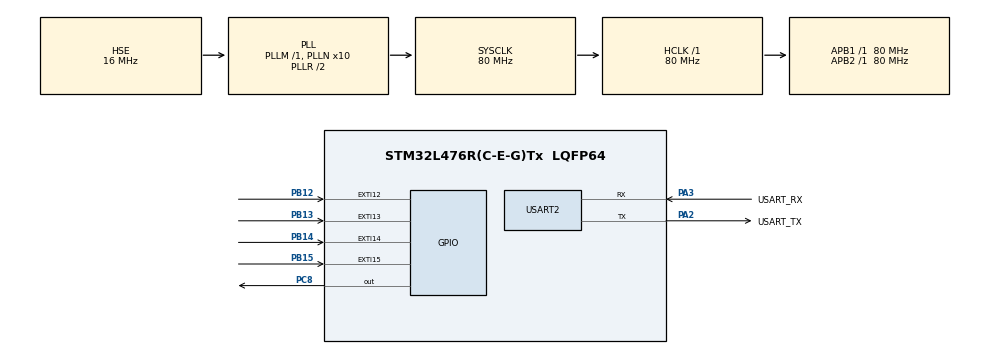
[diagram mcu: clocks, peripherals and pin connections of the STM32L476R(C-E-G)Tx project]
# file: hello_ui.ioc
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Mcu.Family=STM32L4
PA2.GPIO_PuPd=GPIO_NOPULL
VP_SYS_VS_tim6.Mode=TIM6
RCC.CortexFreq_Value=80000000
NVIC.TIM6_DAC_IRQn=true\:0\:0\:false\:false\:true\:false\:false\:true
PH0-OSC_IN\ (PH0).Signal=RCC_OSC_IN
PA3.GPIO_PuPd=GPIO_NOPULL
PA2.GPIO_Speed=GPIO_SPEED_FREQ_VERY_HIGH
PC15-OSC32_OUT\ (PC15).Mode=LSE-External-Oscillator
PA3.GPIO_Speed=GPIO_SPEED_FREQ_VERY_HIGH
PB13.Signal=GPXTI13
PB15.Signal=GPXTI15
RCC.SYSCLKSource=RCC_SYSCLKSOURCE_PLLCLK
ProjectManager.StackSize=0x400
PB3\ (JTDO-TRACESWO).Signal=SYS_JTDO-SWO
PC14-OSC32_IN\ (PC14).Mode=LSE-External-Oscillator
VP_FREERTOS_VS_CMSIS_V2.Mode=CMSIS_V2
PA14\ (JTCK-SWCLK).Signal=SYS_JTCK-SWCLK
RCC.HCLKFreq_Value=80000000
RCC.APB2TimFreq_Value=80000000
RCC.AHBFreq_Value=80000000
RCC.PREFETCH_ENABLE=1
NVIC.EXTI15_10_IRQn=true\:5\:0\:false\:false\:true\:true\:true\:true
PH1-OSC_OUT\ (PH1).Mode=HSE-External-Oscillator
RCC.HSE_VALUE=16000000
USART2.VirtualMode-Asynchronous=VM_ASYNC
Mcu.Package=LQFP64
PB14.GPIO_PuPd=GPIO_PULLUP
NVIC.TimeBase=TIM6_DAC_IRQn
PB15.GPIO_PuPd=GPIO_PULLUP
PA2.GPIO_Label=USART_TX
NVIC.TimeBaseIP=TIM6
RCC.APB1TimFreq_Value=80000000
PA13\ (JTMS-SWDIO).Signal=SYS_JTMS-SWDIO
PH0-OSC_IN\ (PH0).Mode=HSE-External-Oscillator
PA3.Signal=USART2_RX
PA2.GPIO_Mode=GPIO_MODE_AF_PP
PB14.GPIO_ModeDefaultEXTI=GPIO_MODE_IT_FALLING
RCC.MSI_VALUE=4000000
RCC.PLLSourceVirtual=RCC_PLLSOURCE_HSE
PA14\ (JTCK-SWCLK).Mode=Serial_Wire
FREERTOS.Tasks01=defaultTask,24,128,StartDefaultTask,Default,NULL,Dynamic,NULL,NULL
PC8.Signal=GPIO_Output
PC15-OSC32_OUT\ (PC15).Signal=RCC_OSC32_OUT
PA14\ (JTCK-SWCLK).GPIO_Label=TCK
PB3\ (JTDO-TRACESWO).GPIO_Label=SWO
PB13.GPIO_ModeDefaultEXTI=GPIO_MODE_IT_FALLING
PH1-OSC_OUT\ (PH1).Signal=RCC_OSC_OUT
PA3.Mode=Asynchronous
ProjectManager.TargetToolchain=STM32CubeIDE
PA3.GPIO_Mode=GPIO_MODE_AF_PP
RCC.USBFreq_Value=64000000
PB14.Signal=GPXTI14
PB15.GPIO_ModeDefaultEXTI=GPIO_MODE_IT_FALLING
board=NUCLEO-L476RG
RCC.VCOOutputFreq_Value=160000000
PB13.GPIO_PuPd=GPIO_PULLUP
RCC.APB2Freq_Value=80000000
PA13\ (JTMS-SWDIO).GPIO_Label=TMS
RCC.ADCFreq_Value=64000000
Mcu.Name=STM32L476R(C-E-G)Tx
PA2.Signal=USART2_TX
PA13\ (JTMS-SWDIO).Mode=Serial_Wire
RCC.SYSCLKFreq_VALUE=80000000
PC14-OSC32_IN\ (PC14).Signal=RCC_OSC32_IN
ProjectManager.HeapSize=0x200
PB12.GPIO_ModeDefaultEXTI=GPIO_MODE_IT_FALLING
RCC.HSI_VALUE=16000000
NVIC.PriorityGroup=NVIC_PRIORITYGROUP_4
RCC.PLLN=10
PA2.Mode=Asynchronous
PB12.GPIO_PuPd=GPIO_PULLUP
RCC.APB1Freq_Value=80000000
PB12.Signal=GPXTI12
PA3.GPIO_Label=USART_RX

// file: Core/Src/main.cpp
/* USER CODE BEGIN Header */
/**
  ******************************************************************************
  * @file           : main.cpp
  * @brief          : Main program body
  ******************************************************************************
  * @attention
  *
  * <h2><center>&copy; Copyright (c) 2021 STMicroelectronics.
  * All rights reserved.</center></h2>
  *
  * This software component is licensed by ST under BSD 3-Clause license,
  * the "License"; You may not use this file except in compliance with the
  * License. You may obtain a copy of the License at:
  *                        opensource.org/licenses/BSD-3-Clause
  *
  ******************************************************************************
  */
/* USER CODE END Header */
#include "main.h"
#include "cmsis_os.h"

/* USER CODE BEGIN Includes */
#include "ui.h"
/* USER CODE END Includes */

UART_HandleTypeDef huart2;

/* Definitions for defaultTask */
osThreadId_t defaultTaskHandle;
const osThreadAttr_t defaultTask_attributes = {
  .name = "defaultTask",
  .stack_size = 128 * 4,
  .priority = (osPriority_t) osPriorityNormal,
};
/* USER CODE BEGIN PV */
UI xUI(&huart2);
/* USER CODE END PV */

void SystemClock_Config(void);
static void MX_GPIO_Init(void);
static void MX_USART2_UART_Init(void);
void StartDefaultTask(void *argument);

int main(void)
{

  /* MCU Configuration--------------------------------------------------------*/

  /* Reset of all peripherals, Initializes the Flash interface and the Systick. */
  HAL_Init();

  /* Configure the system clock */
  SystemClock_Config();

  /* Initialize all configured peripherals */
  MX_GPIO_Init();
  MX_USART2_UART_Init();

  /* Init scheduler */
  osKernelInitialize();

  /* Create the thread(s) */
  /* creation of defaultTask */
  defaultTaskHandle = osThreadNew(StartDefaultTask, NULL, &defaultTask_attributes);

  /* Start scheduler */
  osKernelStart();

  /* We should never get here as control is now taken by the scheduler */
  /* Infinite loop */
  while (1)
  {

  }
}

void SystemClock_Config(void)
{
  RCC_OscInitTypeDef RCC_OscInitStruct = {0};
  RCC_ClkInitTypeDef RCC_ClkInitStruct = {0};
  RCC_PeriphCLKInitTypeDef PeriphClkInit = {0};

  /** Initializes the RCC Oscillators according to the specified parameters
  * in the RCC_OscInitTypeDef structure.
  */
  RCC_OscInitStruct.OscillatorType = RCC_OSCILLATORTYPE_HSE;
  RCC_OscInitStruct.HSEState = RCC_HSE_ON;
  RCC_OscInitStruct.PLL.PLLState = RCC_PLL_ON;
  RCC_OscInitStruct.PLL.PLLSource = RCC_PLLSOURCE_HSE;
  RCC_OscInitStruct.PLL.PLLM = 1;
  RCC_OscInitStruct.PLL.PLLN = 10;
  RCC_OscInitStruct.PLL.PLLP = RCC_PLLP_DIV7;
  RCC_OscInitStruct.PLL.PLLQ = RCC_PLLQ_DIV2;
  RCC_OscInitStruct.PLL.PLLR = RCC_PLLR_DIV2;
  if (HAL_RCC_OscConfig(&RCC_OscInitStruct) != HAL_OK)
  {
    Error_Handler();
  }
  /** Initializes the CPU, AHB and APB buses clocks
  */
  RCC_ClkInitStruct.ClockType = RCC_CLOCKTYPE_HCLK|RCC_CLOCKTYPE_SYSCLK
                              |RCC_CLOCKTYPE_PCLK1|RCC_CLOCKTYPE_PCLK2;
  RCC_ClkInitStruct.SYSCLKSource = RCC_SYSCLKSOURCE_PLLCLK;
  RCC_ClkInitStruct.AHBCLKDivider = RCC_SYSCLK_DIV1;
  RCC_ClkInitStruct.APB1CLKDivider = RCC_HCLK_DIV1;
  RCC_ClkInitStruct.APB2CLKDivider = RCC_HCLK_DIV1;

  if (HAL_RCC_ClockConfig(&RCC_ClkInitStruct, FLASH_LATENCY_4) != HAL_OK)
  {
    Error_Handler();
  }
  PeriphClkInit.PeriphClockSelection = RCC_PERIPHCLK_USART2;
  PeriphClkInit.Usart2ClockSelection = RCC_USART2CLKSOURCE_PCLK1;
  if (HAL_RCCEx_PeriphCLKConfig(&PeriphClkInit) != HAL_OK)
  {
    Error_Handler();
  }
  /** Configure the main internal regulator output voltage
  */
  if (HAL_PWREx_ControlVoltageScaling(PWR_REGULATOR_VOLTAGE_SCALE1) != HAL_OK)
  {
    Error_Handler();
  }
}

static void MX_USART2_UART_Init(void)
{

  huart2.Instance = USART2;
  huart2.Init.BaudRate = 115200;
  huart2.Init.WordLength = UART_WORDLENGTH_8B;
  huart2.Init.StopBits = UART_STOPBITS_1;
  huart2.Init.Parity = UART_PARITY_NONE;
  huart2.Init.Mode = UART_MODE_TX_RX;
  huart2.Init.HwFlowCtl = UART_HWCONTROL_NONE;
  huart2.Init.OverSampling = UART_OVERSAMPLING_16;
  huart2.Init.OneBitSampling = UART_ONE_BIT_SAMPLE_DISABLE;
  huart2.AdvancedInit.AdvFeatureInit = UART_ADVFEATURE_NO_INIT;
  if (HAL_UART_Init(&huart2) != HAL_OK)
  {
    Error_Handler();
  }

}

static void MX_GPIO_Init(void)
{
  GPIO_InitTypeDef GPIO_InitStruct = {0};

  /* GPIO Ports Clock Enable */
  __HAL_RCC_GPIOC_CLK_ENABLE();
  __HAL_RCC_GPIOH_CLK_ENABLE();
  __HAL_RCC_GPIOA_CLK_ENABLE();
  __HAL_RCC_GPIOB_CLK_ENABLE();

  /*Configure GPIO pin Output Level */
  HAL_GPIO_WritePin(GPIOC, GPIO_PIN_8, GPIO_PIN_RESET);

  /*Configure GPIO pins : PB12 PB13 PB14 PB15 */
  GPIO_InitStruct.Pin = GPIO_PIN_12|GPIO_PIN_13|GPIO_PIN_14|GPIO_PIN_15;
  GPIO_InitStruct.Mode = GPIO_MODE_IT_FALLING;
  GPIO_InitStruct.Pull = GPIO_PULLUP;
  HAL_GPIO_Init(GPIOB, &GPIO_InitStruct);

  /*Configure GPIO pin : PC8 */
  GPIO_InitStruct.Pin = GPIO_PIN_8;
  GPIO_InitStruct.Mode = GPIO_MODE_OUTPUT_PP;
  GPIO_InitStruct.Pull = GPIO_NOPULL;
  GPIO_InitStruct.Speed = GPIO_SPEED_FREQ_LOW;
  HAL_GPIO_Init(GPIOC, &GPIO_InitStruct);

  /* EXTI interrupt init*/
  HAL_NVIC_SetPriority(EXTI15_10_IRQn, 5, 0);
  HAL_NVIC_EnableIRQ(EXTI15_10_IRQn);

}

/* USER CODE BEGIN 4 */

#define UP_BUTTON			GPIO_PIN_15
#define DOWN_BUTTON 	GPIO_PIN_14
#define LEFT_BUTTON 	GPIO_PIN_13
#define RIGHT_BUTTON 	GPIO_PIN_12

void HAL_GPIO_EXTI_Callback(uint16_t GPIO_Pin)
{
	xUI.vEXTI(GPIO_Pin);
}
/* USER CODE END 4 */

void StartDefaultTask(void *argument)
{
  /* USER CODE BEGIN 5 */
  /* Infinite loop */
  for(;;)
  {
  	//HAL_UART_Transmit(&huart2, (uint8_t *)("hello\r\n"), sizeof("hello\r\n"), 100);
  	xUI.vUpdate();
    osDelay(250);
  }
  /* USER CODE END 5 */
}

 /**
  * @brief  Period elapsed callback in non blocking mode
  * @note   This function is called  when TIM6 interrupt took place, inside
  * HAL_TIM_IRQHandler(). It makes a direct call to HAL_IncTick() to increment
  * a global variable "uwTick" used as application time base.
  * @param  htim : TIM handle
  * @retval None
  */
void HAL_TIM_PeriodElapsedCallback(TIM_HandleTypeDef *htim)
{
  if (htim->Instance == TIM6) {
    HAL_IncTick();
  }
}

void Error_Handler(void)
{
  __disable_irq();
  while (1)
  {
  }
}

/************************ (C) COPYRIGHT STMicroelectronics *****END OF FILE****/
